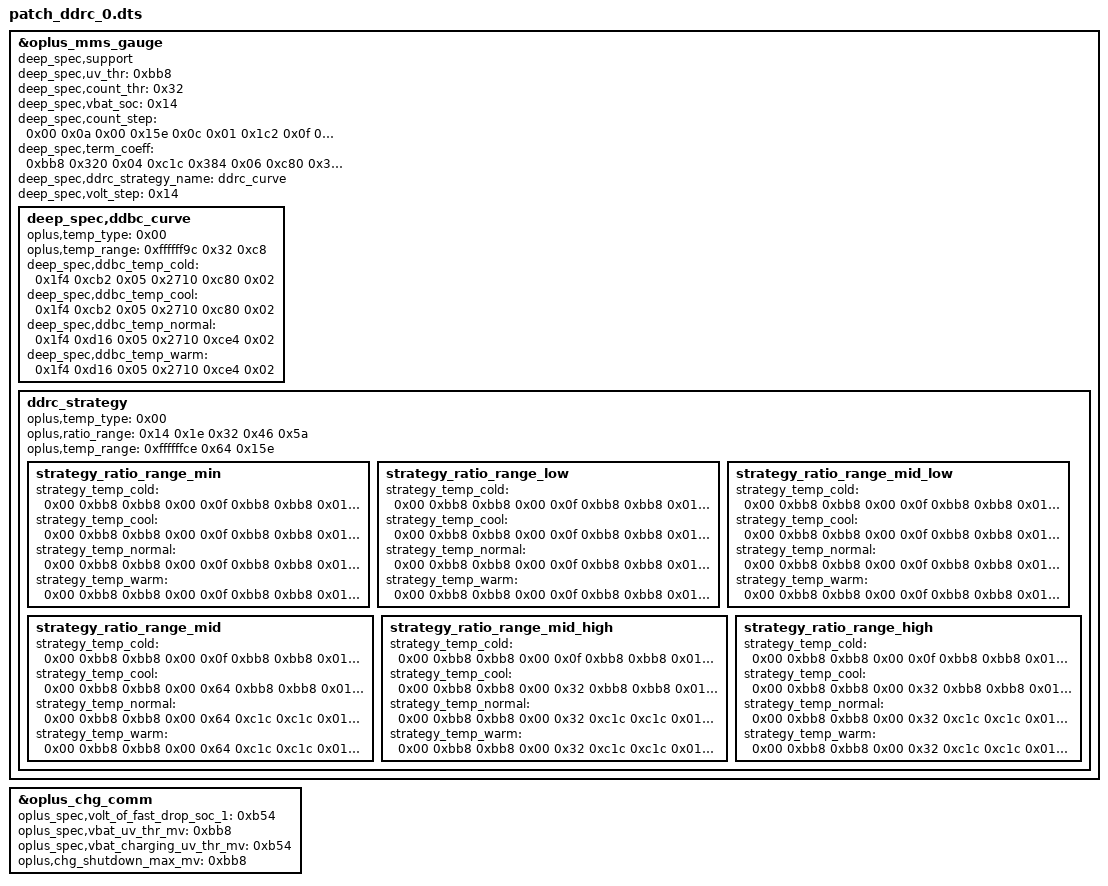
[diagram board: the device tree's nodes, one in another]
/dts-v1/;
/plugin/;

/ {
	fragment@0 {
		target = <&oplus_mms_gauge>;
		__overlay__ {
			deep_spec,support;
			deep_spec,uv_thr = <0xbb8>;
			deep_spec,count_thr = <0x32>;
			deep_spec,vbat_soc = <0x14>;
			deep_spec,count_step = <0x00 0x0a 0x00 0x15e 0x0c 0x01 0x1c2 0x0f 0x02 0x212 0x14 0x03>;
			deep_spec,term_coeff = <0xbb8 0x320 0x04 0xc1c 0x384 0x06 0xc80 0x3e8 0x09 0xce4 0x44c 0x0a>;
			deep_spec,ddrc_strategy_name = "ddrc_curve";
			deep_spec,volt_step = <0x14>;
			
			deep_spec,ddbc_curve {
				oplus,temp_type = <0x00>;
				oplus,temp_range = <0xffffff9c 0x32 0xc8>;
				deep_spec,ddbc_temp_cold = <0x1f4 0xcb2 0x05 0x2710 0xc80 0x02>;
				deep_spec,ddbc_temp_cool = <0x1f4 0xcb2 0x05 0x2710 0xc80 0x02>;
				deep_spec,ddbc_temp_normal = <0x1f4 0xd16 0x05 0x2710 0xce4 0x02>;
				deep_spec,ddbc_temp_warm = <0x1f4 0xd16 0x05 0x2710 0xce4 0x02>;
			};
			
			ddrc_strategy {
				oplus,temp_type = <0x00>;
				oplus,ratio_range = <0x14 0x1e 0x32 0x46 0x5a>;
				oplus,temp_range = <0xffffffce 0x64 0x15e>;
				
				strategy_ratio_range_min {
					strategy_temp_cold = <0x00 0xbb8 0xbb8 0x00 0x0f 0xbb8 0xbb8 0x01 0x4b0 0xc1c 0xc1c 0x02 0x640 0xc80 0xc80 0x03 0x7d0 0xce4 0xce4 0x04>;
					strategy_temp_cool = <0x00 0xbb8 0xbb8 0x00 0x0f 0xbb8 0xbb8 0x01 0x1f4 0xbb8 0xbb8 0x02 0x3e8 0xc1c 0xc1c 0x03 0x5dc 0xc80 0xc80 0x04 0x7d0 0xce4 0xce4 0x05>;
					strategy_temp_normal = <0x00 0xbb8 0xbb8 0x00 0x0f 0xbb8 0xbb8 0x01 0x1f4 0xc1c 0xc1c 0x02 0x3e8 0xc80 0xc80 0x03 0x5dc 0xce4 0xce4 0x04>;
					strategy_temp_warm = <0x00 0xbb8 0xbb8 0x00 0x0f 0xbb8 0xbb8 0x01 0x1f4 0xc1c 0xc1c 0x02 0x3e8 0xc80 0xc80 0x03 0x5dc 0xce4 0xce4 0x04>;
				};
				
				strategy_ratio_range_low {
					strategy_temp_cold = <0x00 0xbb8 0xbb8 0x00 0x0f 0xbb8 0xbb8 0x01 0x3e8 0xc1c 0xc1c 0x02 0x514 0xc80 0xc80 0x03 0x640 0xce4 0xce4 0x04>;
					strategy_temp_cool = <0x00 0xbb8 0xbb8 0x00 0x0f 0xbb8 0xbb8 0x01 0x190 0xbb8 0xbb8 0x02 0x320 0xc1c 0xc1c 0x03 0x4b0 0xc80 0xc80 0x04 0x640 0xce4 0xce4 0x05>;
					strategy_temp_normal = <0x00 0xbb8 0xbb8 0x00 0x0f 0xbb8 0xbb8 0x01 0x190 0xc1c 0xc1c 0x02 0x320 0xc80 0xc80 0x03 0x4b0 0xce4 0xce4 0x04>;
					strategy_temp_warm = <0x00 0xbb8 0xbb8 0x00 0x0f 0xbb8 0xbb8 0x01 0x190 0xc1c 0xc1c 0x02 0x320 0xc80 0xc80 0x03 0x4b0 0xce4 0xce4 0x04>;
				};
				
				strategy_ratio_range_mid_low {
					strategy_temp_cold = <0x00 0xbb8 0xbb8 0x00 0x0f 0xbb8 0xbb8 0x01 0x258 0xc1c 0xc1c 0x02 0x384 0xc80 0xc80 0x03 0x4b0 0xce4 0xce4 0x04>;
					strategy_temp_cool = <0x00 0xbb8 0xbb8 0x00 0x0f 0xbb8 0xbb8 0x01 0x12c 0xc1c 0xc1c 0x02 0x258 0xc80 0xc80 0x03 0x384 0xc80 0xc80 0x04 0x4b0 0xce4 0xce4 0x05>;
					strategy_temp_normal = <0x00 0xbb8 0xbb8 0x00 0x0f 0xbb8 0xbb8 0x01 0x12c 0xc1c 0xc1c 0x02 0x258 0xc80 0xc80 0x03 0x384 0xce4 0xce4 0x04>;
					strategy_temp_warm = <0x00 0xbb8 0xbb8 0x00 0x0f 0xbb8 0xbb8 0x01 0x12c 0xc1c 0xc1c 0x02 0x258 0xc80 0xc80 0x03 0x384 0xce4 0xce4 0x04>;
				};
				
				strategy_ratio_range_mid {
					strategy_temp_cold = <0x00 0xbb8 0xbb8 0x00 0x0f 0xbb8 0xbb8 0x01 0x190 0xc1c 0xc1c 0x02 0x2bc 0xc80 0xc80 0x03 0x3e8 0xce4 0xce4 0x04>;
					strategy_temp_cool = <0x00 0xbb8 0xbb8 0x00 0x64 0xbb8 0xbb8 0x01 0xc8 0xc1c 0xc1c 0x02 0x1f4 0xc80 0xc80 0x03 0x320 0xce4 0xce4 0x04>;
					strategy_temp_normal = <0x00 0xbb8 0xbb8 0x00 0x64 0xc1c 0xc1c 0x01 0xc8 0xc80 0xc80 0x02 0x1f4 0xce4 0xce4 0x03>;
					strategy_temp_warm = <0x00 0xbb8 0xbb8 0x00 0x64 0xc1c 0xc1c 0x01 0xc8 0xc80 0xc80 0x02 0x1f4 0xce4 0xce4 0x03>;
				};
				
				strategy_ratio_range_mid_high {
					strategy_temp_cold = <0x00 0xbb8 0xbb8 0x00 0x0f 0xbb8 0xbb8 0x01 0x96 0xc1c 0xc1c 0x02 0x12c 0xc80 0xc80 0x03 0x1f4 0xce4 0xce4 0x04>;
					strategy_temp_cool = <0x00 0xbb8 0xbb8 0x00 0x32 0xbb8 0xbb8 0x01 0x64 0xc1c 0xc1c 0x02 0x96 0xc80 0xc80 0x03 0x12c 0xce4 0xce4 0x04>;
					strategy_temp_normal = <0x00 0xbb8 0xbb8 0x00 0x32 0xc1c 0xc1c 0x01 0x64 0xc80 0xc80 0x02 0x96 0xce4 0xce4 0x03>;
					strategy_temp_warm = <0x00 0xbb8 0xbb8 0x00 0x32 0xc1c 0xc1c 0x01 0x64 0xc80 0xc80 0x02 0x96 0xce4 0xce4 0x03>;
				};
				
				strategy_ratio_range_high {
					strategy_temp_cold = <0x00 0xbb8 0xbb8 0x00 0x0f 0xbb8 0xbb8 0x01 0x96 0xc1c 0xc1c 0x02 0x12c 0xc80 0xc80 0x03 0x1f4 0xce4 0xce4 0x04>;
					strategy_temp_cool = <0x00 0xbb8 0xbb8 0x00 0x32 0xbb8 0xbb8 0x01 0x64 0xc1c 0xc1c 0x02 0x96 0xc80 0xc80 0x03 0x12c 0xce4 0xce4 0x04>;
					strategy_temp_normal = <0x00 0xbb8 0xbb8 0x00 0x32 0xc1c 0xc1c 0x01 0x64 0xc80 0xc80 0x02 0x96 0xce4 0xce4 0x03>;
					strategy_temp_warm = <0x00 0xbb8 0xbb8 0x00 0x32 0xc1c 0xc1c 0x01 0x64 0xc80 0xc80 0x02 0x96 0xce4 0xce4 0x03>;
				};
			};
		};
	};
	
	fragment@1 {
		target = <&oplus_chg_comm>;
		__overlay__ {
			oplus_spec,volt_of_fast_drop_soc_1 = <0xb54>;
			oplus_spec,vbat_uv_thr_mv = <0xbb8>;
			oplus_spec,vbat_charging_uv_thr_mv = <0xb54>;
			oplus,chg_shutdown_max_mv = <0xbb8>;
		};
	};
};
